# HM1030 register map
File version: 0.1
Registers are 32-bit, read-write, reset 0x0 unless marked. A register's access mark holds for its fields unless they carry their own. Offsets are from the block's base; [hi:lo] are bit positions; lines under a group give offsets from that group.

## RTC — Registers group
Base 0x40069000
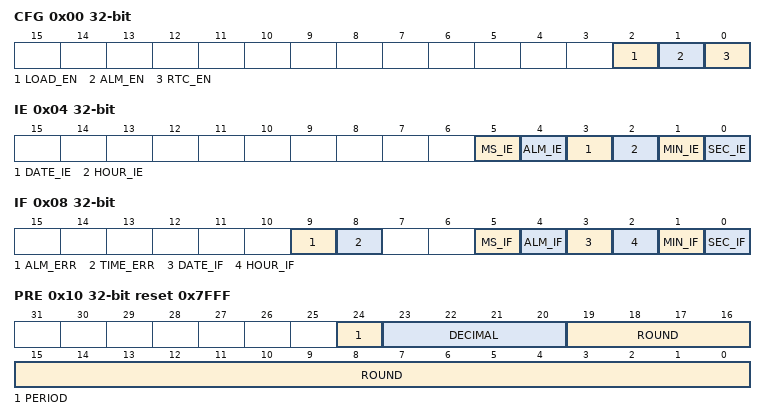
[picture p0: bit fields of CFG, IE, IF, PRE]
0x00 CFG — 配置寄存器
  [2] LOAD_EN — RTC加载寄存器TR和DR时间设定值
  [1] ALM_EN — RTC 闹钟功能使能位
  [0] RTC_EN — RTC 使能位
0x04 IE — 中断使能寄存器
  [5] MS_IE — 1/2秒中断使能位
  [4] ALM_IE — 闹钟中断使能位
  [3] DATE_IE — 日中断使能位
  [2] HOUR_IE — 小时中断使能位
  [1] MIN_IE — 分钟中断使能位
  [0] SEC_IE — 秒中断使能位
0x08 IF — 状态寄存器
  [9] ALM_ERR — 闹钟设定有效标志位
  [8] TIME_ERR — 时间设定有效标志位
  [5] MS_IF — 1/2秒中断响应
  [4] ALM_IF — 闹钟中断响应
  [3] DATE_IF — 日中断响应
  [2] HOUR_IF — 小时中断响应
  [1] MIN_IF — 分钟中断响应
  [0] SEC_IF — 秒中断响应
0x10 PRE reset 0x7FFF — 预分频寄存器
  [24] PERIOD — 小数计算周期选择
  [23:20] DECIMAL — 预分频小数部分
  [19:0] ROUND — 预分频整数部分
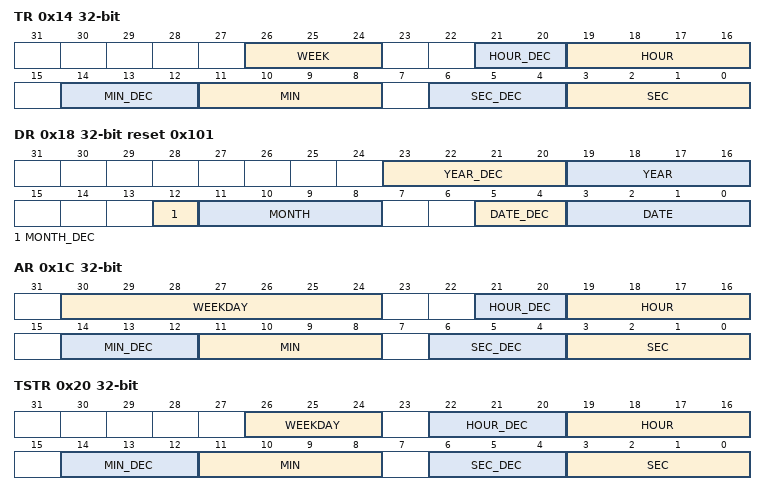
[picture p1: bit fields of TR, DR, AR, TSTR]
0x14 TR — 时间寄存器
  [26:24] WEEK — 设定时间所属星期
  [21:20] HOUR_DEC — 设定时间所属小时的十位数
  [19:16] HOUR — 设定时间所属小时的个位数
  [14:12] MIN_DEC — 设定时间所属分钟的十位数
  [11:8] MIN — 设定时间所属分钟的个位数
  [6:4] SEC_DEC — 设定时间所属秒钟的十位数
  [3:0] SEC — 设定时间所属秒钟的个位数
0x18 DR reset 0x101 — 日期寄存器
  [23:20] YEAR_DEC — 设定时间所属月份的十位数
  [19:16] YEAR — 设定时间所属月份的个位数
  [12] MONTH_DEC — 设定时间所属月份的十位数
  [11:8] MONTH — 设定时间所属月份的个位数
  [5:4] DATE_DEC — 设定时间所属日期的十位数
  [3:0] DATE — 设定时间所属日期的个位数
0x1C AR — 闹钟寄存器
  [30:24] WEEKDAY — 闹钟时间所属星期
  [21:20] HOUR_DEC — 闹钟时间所属小时的十位数
  [19:16] HOUR — 闹钟时间所属小时的个位数
  [14:12] MIN_DEC — 闹钟时间所属分钟的十位数
  [11:8] MIN — 闹钟时间所属分钟的个位数
  [6:4] SEC_DEC — 闹钟时间所属秒钟的十位数
  [3:0] SEC — 闹钟时间所属秒钟的个位数
0x20 TSTR — 当前时间寄存器
  [26:24] WEEKDAY — 当前时间所属星期
  [22:20] HOUR_DEC — 当前时间所属小时的十位数
  [19:16] HOUR — 当前时间所属小时的个位数
  [14:12] MIN_DEC — 当前时间所属分钟的十位数
  [11:8] MIN — 当前时间所属分钟的个位数
  [6:4] SEC_DEC — 当前时间所属秒钟的十位数
  [3:0] SEC — 当前时间所属秒钟的个位数
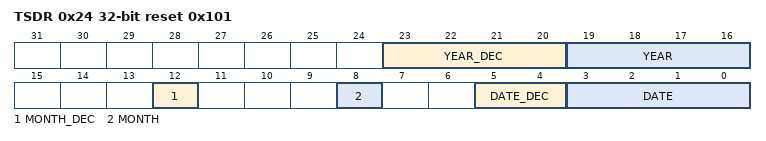
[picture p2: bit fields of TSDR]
0x24 TSDR reset 0x101 — 当前日期寄存器
  [23:20] YEAR_DEC — 当前时间所属的纪年的十位数
  [19:16] YEAR — 当前时间所属的纪年的个位数
  [12] MONTH_DEC — 当前时间所属的月份的十位数
  [8] MONTH — 当前时间所属的月份的个位数
  [5:4] DATE_DEC — 当前时间所属的日期的十位数
  [3:0] DATE — 当前时间所属的日期的个位数e
0x28 CNT reset 0x7FFFF — 秒标当前计数值
  [19:0] CNT_15 — 20bit计数位
0x2C VALID — 当前时间有效标志寄存器
  [0] CUR_VALID — 当前时间有效标志位

## IWDT — Registers group
Base 0x4006A000
0x00 LOAD — 初值寄存器
  [19:0] IWDTLOAD — IWDT计数器的初始值配置寄存器
0x04 VALUE ro
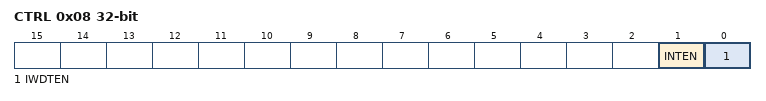
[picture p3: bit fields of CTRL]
0x08 CTRL
  [1] INTEN — IWDT中断使能位
  [0] IWDTEN — IWDT启动位
0x0C IF — IWDT状态位
  [0] IF
0x10 FEED — 写0x55喂狗
  [7:0] FEED

## WWDT — Registers group
Base 0x4006A800
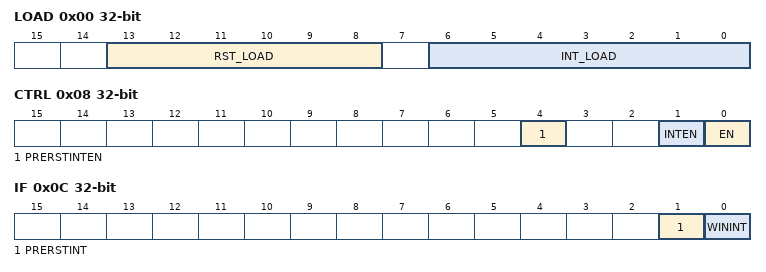
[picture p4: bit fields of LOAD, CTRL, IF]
0x00 LOAD — 初值寄存器
  [13:8] RST_LOAD — 窗口复位比较值寄存器
  [6:0] INT_LOAD — 窗口中断比较值寄存器
0x04 VALUE ro
  [6:0] VALUE rw — 计数值寄存器
0x08 CTRL
  [4] PRERSTINTEN — 预复位中断使能位
  [1] INTEN — 中断使能位
  [0] EN — 启动位
0x0C IF — IWDT状态位
  [1] PRERSTINT — 预复位中断标志位
  [0] WININT — 窗口中断标志位
0x10 FEED — 写0x55喂狗
  [7:0] FEED

## UART0 — Registers group
Base 0x4006B000
Same registers: UART1 0x4006B800, UART2 0x4006C000
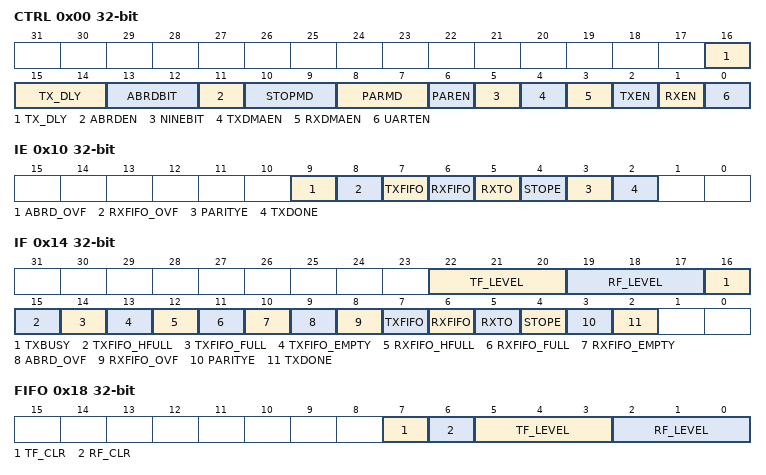
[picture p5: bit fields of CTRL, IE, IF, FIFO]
0x00 CTRL — 控制寄存器
  [16:14] TX_DLY — 发送延迟时间设置
  [13:12] ABRDBIT — 自动波特率检测位长配置
  [11] ABRDEN — 自动波特率检测使能
  [10:9] STOPMD — 发送STOP位长度选择
  [8:7] PARMD — 奇偶校验模式选择
  [6] PAREN — 奇偶校验位使能
  [5] NINEBIT — 9bit数据模式使能
  [4] TXDMAEN — 发送DMA传输使能
  [3] RXDMAEN — 接收DMA传输使能
  [2] TXEN — 发送使能位
  [1] RXEN — 接收使能位
  [0] UARTEN — UART使能位
0x04 BAUD — 波特率配置寄存器
  [15:0] BAUD — 波特率配置数据
0x08 TDR — 写数据寄存器
  [8:0] TDR
0x0C RDR ro — 读数据寄存器
  [8:0] RDR
0x10 IE — 中断使能寄存器
  [9] ABRD_OVF — 自动波特率检测功能计数器溢出中断使能
  [8] RXFIFO_OVF — 接收FIFO溢出中断使能
  [7] TXFIFO — 发送FIFO中保存的数据达到设定水位中断使能
  [6] RXFIFO — 接收FIFO中接收的数据达到设定水位中断使能
  [5] RXTO — 接收超时中断使能
  [4] STOPE — 接收数据出现停止位错误中断使能
  [3] PARITYE — 接收数据出现奇偶校验错中断使能
  [2] TXDONE — 全部数据发送完成中断使能
0x14 IF — 中断状态寄存器
  [22:20] TF_LEVEL ro — 发送FIFO水位标志信号
  [19:17] RF_LEVEL ro — 接收FIFO水位标志信号
  [16] TXBUSY ro — 数据发送忙标志
  [15] TXFIFO_HFULL ro — 发送FIFO半满标志
  [14] TXFIFO_FULL ro — 发送FIFO满标志
  [13] TXFIFO_EMPTY ro — 发送FIFO空标志
  [12] RXFIFO_HFULL ro — 接收FIFO半满标志
  [11] RXFIFO_FULL ro — 接收FIFO满标志
  [10] RXFIFO_EMPTY ro — 接收FIFO空标志
  [9] ABRD_OVF — 自动波特率检测功能计数器溢出标志
  [8] RXFIFO_OVF — 接收FIFO溢出标志
  [7] TXFIFO — 发送FIFO中保存的数据达到设定水位
  [6] RXFIFO — 接收FIFO中接收到的数据达到设定水位
  [5] RXTO — 接收超时标志
  [4] STOPE — 接收数据出现停止位错误
  [3] PARITYE — 接收数据出现奇偶校验错
  [2] TXDONE — 全部数据发送完成
0x18 FIFO — FIFO控制寄存器
  [7] TF_CLR — TXFIFO清除使能
  [6] RF_CLR — RXFIFO清除使能
  [5:3] TF_LEVEL — 用于TXFIFO产生中断的水位设置
  [2:0] RF_LEVEL — 用于RXFIFO产生中断的水位设置
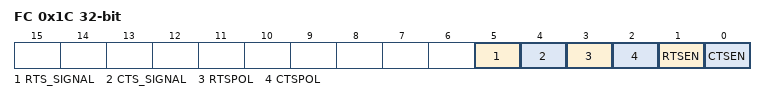
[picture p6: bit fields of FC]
0x1C FC — 流控制配置寄存器
  [5] RTS_SIGNAL ro — 表示线上RTS状态
  [4] CTS_SIGNAL ro — 表示线上CTS状态
  [3] RTSPOL — RTS信号极性配置
  [2] CTSPOL — CTS信号极性配置
  [1] RTSEN — RTS流控使能
  [0] CTSEN — CTS流控使能
0x20 RXTO — 接收超时配置寄存器
  [7:0] RXTO — 接收数据超时触发比较值
